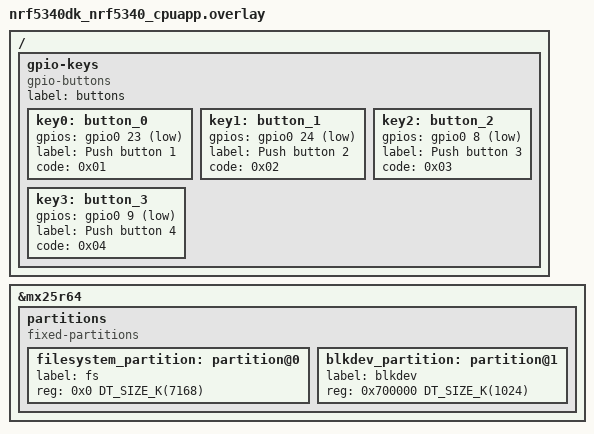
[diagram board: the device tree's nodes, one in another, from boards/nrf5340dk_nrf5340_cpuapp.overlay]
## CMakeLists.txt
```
# Application
cmake_minimum_required(VERSION 3.13.1)

include(../cmake/modules.cmake)
find_package(Zephyr REQUIRED HINTS $ENV{ZEPHYR_BASE})
project(firmware)

#=======================
# User extension
#=======================
include(../cmake/extensions.cmake)
include(../cmake/debugger.cmake)

#=======================
# Global include path
#=======================
zephyr_include_directories(.)

#===========================
# Subdirectories and target
#===========================
add_subdirectory(component)
target_sources(app PRIVATE
  src/main.c
  src/apple_ancs.c
  src/apple_ams.c
  src/bt_disc.c
  src/timer_ii.c
  src/timer_ii_zephyr.c
  src/timer_ii_test.c
)
collect_link_libraries(applibs app)
target_link_libraries(app PUBLIC ${applibs})
```

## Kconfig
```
#Application
menu "Application configuration"
rsource "component/Kconfig"
endmenu

# System
source "Kconfig.zephyr"
```

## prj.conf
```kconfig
CONFIG_BT=y
CONFIG_BT_DEBUG_LOG=y
CONFIG_BT_SMP=y
CONFIG_BT_PERIPHERAL=y
CONFIG_BT_DIS=y
CONFIG_BT_DIS_PNP=n
CONFIG_BT_BAS=y
CONFIG_BT_HRS=y
CONFIG_BT_DEVICE_NAME="ZephyrBLE"
CONFIG_BT_DEVICE_APPEARANCE=833

#Filesystem 
CONFIG_NVS=y

#Settings
CONFIG_SETTINGS=y
CONFIG_SETTINGS_NVS=y

CONFIG_USER_LIBRARIES=y
CONFIG_CORTEXM_DEBUGGER=y

CONFIG_LOG=y
CONFIG_LOG_BACKEND_UART=y

CONFIG_CACHE_MANAGEMENT=y
CONFIG_DCACHE_LINE_SIZE=32
CONFIG_ICACHE_LINE_SIZE=32

CONFIG_HEAP_MEM_POOL_SIZE=65536

# Debug
CONFIG_ASSERT=y

#RootKit
CONFIG_BT_ANCS_CLIENT=y
CONFIG_BT_ANCS_CLIENT_CP_BUFF_SIZE=256
CONFIG_BT_GATT_DM=y
CONFIG_BT_AMS_CLIENT=y
CONFIG_BT_GATTP=y
```

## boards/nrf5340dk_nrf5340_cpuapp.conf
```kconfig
#======================
# ARM options
#======================
CONFIG_NULL_POINTER_EXCEPTION_DETECTION_MPU=y

#======================
# Kernel
#======================
CONFIG_MAIN_STACK_SIZE=2048
CONFIG_SCHED_MULTIQ=y
CONFIG_THREAD_MONITOR=y
CONFIG_THREAD_NAME=y
CONFIG_THREAD_RUNTIME_STATS=y
CONFIG_SYSTEM_WORKQUEUE_STACK_SIZE=2048
CONFIG_KERNEL_MEM_POOL=y
CONFIG_HEAP_MEM_POOL_SIZE=65536

#======================
# Cache
#======================
CONFIG_CACHE_MANAGEMENT=y

#======================
# FPU
#======================
CONFIG_FPU=y
CONFIG_FPU_SHARING=y

#======================
# Subsystem
#======================

# BLE-HOST
CONFIG_BT_SHELL=y
CONFIG_BT=y
CONFIG_BT_HCI=y

CONFIG_BT_BUF_ACL_TX_SIZE=251
CONFIG_BT_BUF_ACL_RX_SIZE=512

CONFIG_BT_DEVICE_NAME_DYNAMIC=y
CONFIG_BT_DEVICE_NAME_MAX=32
CONFIG_BT_DEVICE_NAME="NordicBLE"
CONFIG_BT_COMPANY_ID=0x05F1

CONFIG_BT_DEBUG_LOG=y
CONFIG_BT_PERIPHERAL=y
CONFIG_BT_DIS=y
CONFIG_BT_HCI_ACL_FLOW_CONTROL=y
CONFIG_BT_PHY_UPDATE=y
CONFIG_BT_DATA_LEN_UPDATE=y
CONFIG_BT_SMP=y

CONFIG_BT_L2CAP_TX_BUF_COUNT=6
CONFIG_BT_L2CAP_TX_FRAG_COUNT=4
CONFIG_BT_L2CAP_TX_MTU=256

CONFIG_BT_GATT_SERVICE_CHANGED=y
CONFIG_BT_GATT_CLIENT=y
CONFIG_BT_GATT_READ_MULTIPLE=y

CONFIG_BT_GAP_AUTO_UPDATE_CONN_PARAMS=y
CONFIG_BT_GAP_PERIPHERAL_PREF_PARAMS=y
CONFIG_BT_PERIPHERAL_PREF_MIN_INT=24
CONFIG_BT_PERIPHERAL_PREF_MAX_INT=40
CONFIG_BT_PERIPHERAL_PREF_LATENCY=0
CONFIG_BT_PERIPHERAL_PREF_TIMEOUT=42

CONFIG_BT_HCI_VS=y
CONFIG_BT_HCI_VS_EXT=y
CONFIG_BT_RX_STACK_SIZE=4096
CONFIG_BT_SETTINGS=y
#CONFIG_BT_SHELL=y

# USB
CONFIG_USB_DEVICE_STACK=y
CONFIG_USB_MAX_NUM_TRANSFERS=8
CONFIG_USB_REQUEST_BUFFER_SIZE=512
CONFIG_USB_MASS_STORAGE=y
CONFIG_MASS_STORAGE_DISK_NAME="NAND"
CONFIG_USB_DEVICE_MANUFACTURER="Nordic"
CONFIG_MASS_STORAGE_INQ_VENDOR_ID="Norflash"
CONFIG_MASS_STORAGE_INQ_PRODUCT_ID="USB-Disk        "
CONFIG_USB_DEVICE_VID=0xFFFF
CONFIG_USB_DEVICE_PID=0x1234

#Flash map
CONFIG_FLASH_MAP=y

# Filesystem
CONFIG_FILE_SYSTEM=y
CONFIG_FILE_SYSTEM_SHELL=y

# Little fs
# CONFIG_FILE_SYSTEM_LITTLEFS=y
# CONFIG_FS_LITTLEFS_NUM_FILES=4
# CONFIG_FS_LITTLEFS_NUM_DIRS=4
# CONFIG_FS_LITTLEFS_READ_SIZE=512
# CONFIG_FS_LITTLEFS_PROG_SIZE=512
# CONFIG_FS_LITTLEFS_CACHE_SIZE=4096
# CONFIG_FS_LITTLEFS_LOOKAHEAD_SIZE=128

# Fat
CONFIG_FAT_FILESYSTEM_ELM=y
CONFIG_FS_FATFS_EXFAT=y
CONFIG_FS_FATFS_NUM_FILES=4
CONFIG_FS_FATFS_NUM_DIRS=4
CONFIG_FS_FATFS_LFN=y
CONFIG_FS_FATFS_LFN_MODE_HEAP=y


# Shell
CONFIG_SHELL=y
#CONFIG_UART_SHELL_ON_DEV_NAME="UART_0"

# System monitor
CONFIG_THREAD_ANALYZER=y

# Statistics support
CONFIG_STATS=y
CONFIG_STATS_NAMES=y

#=======================
# Device drivers
#=======================

#Flash driver
CONFIG_FLASH=y
#CONFIG_FLASH_HAS_PAGE_LAYOUT=y
CONFIG_NORDIC_QSPI_NOR=y
CONFIG_NORDIC_QSPI_NOR_FLASH_LAYOUT_PAGE_SIZE=4096

# Disk driver for flash
CONFIG_DISK_DRIVER_FLASH=y
CONFIG_DISK_FLASH_VOLUME_NAME="NAND"
CONFIG_DISK_FLASH_DEV_NAME="MX25R64"
CONFIG_DISK_FLASH_START=0x0
CONFIG_DISK_FLASH_MAX_RW_SIZE=512
CONFIG_DISK_FLASH_ERASE_ALIGNMENT=0x1000
CONFIG_DISK_ERASE_BLOCK_SIZE=0x1000
CONFIG_DISK_FLASH_SECTOR_SIZE=512
CONFIG_DISK_VOLUME_SIZE=0x800000

# BT
CONFIG_BT_RPMSG=y
CONFIG_BT_RPMSG_NRF53=y
CONFIG_BT_DRIVER_QUIRK_NO_AUTO_DLE=y

# IPM
CONFIG_IPM=y
CONFIG_IPM_NRFX=y
CONFIG_IPM_MSG_CH_0_ENABLE=y
CONFIG_IPM_MSG_CH_0_TX=y
CONFIG_IPM_MSG_CH_1_ENABLE=y
CONFIG_IPM_MSG_CH_1_RX=y

# PWM
CONFIG_PWM=y
CONFIG_PWM_NRFX=y
CONFIG_PWM_SHELL=y

# USB
CONFIG_USB_DEVICE_DRIVER=y
CONFIG_USB_NRFX=y

# Kscan
CONFIG_KSCAN=y

#=======================
# C Library
#=======================
CONFIG_NEWLIB_LIBC=y


#=======================
# Compile options
#=======================
# CONFIG_SPEED_OPTIMIZATIONS=y
CONFIG_DEBUG_OPTIMIZATIONS=y


#=========================
# RootKit
#=========================

# Drivers
#CONFIG_GPIO_KEYS=y

# Lib
CONFIG_USER_SYSTEM_INIT=y
CONFIG_USER_FS_MOUNT=y

# Subsystem
CONFIG_USER_SUBSYSTEM=y
CONFIG_BDBUF=y
```

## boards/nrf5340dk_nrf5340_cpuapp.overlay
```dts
/ {
	gpio-keys {
		compatible = "gpio-buttons";
		label = "buttons";
		key0: button_0 {
			gpios = <&gpio0 23 (GPIO_PULL_UP | GPIO_ACTIVE_LOW)>;
			label = "Push button 1";
			code = <0x01>;
		};
		key1: button_1 {
			gpios = <&gpio0 24 (GPIO_PULL_UP | GPIO_ACTIVE_LOW)>;
			label = "Push button 2";
			code = <0x02>;
		};
		key2: button_2 {
			gpios = <&gpio0 8 (GPIO_PULL_UP | GPIO_ACTIVE_LOW)>;
			label = "Push button 3";
			code = <0x03>;
		};
		key3: button_3 {
			gpios = <&gpio0 9 (GPIO_PULL_UP | GPIO_ACTIVE_LOW)>;
			label = "Push button 4";
			code = <0x04>;
		};
	};
};

&mx25r64 {
	partitions {
		compatible = "fixed-partitions";
		#address-cells = <1>;
		#size-cells = <1>;

		filesystem_partition: partition@0 {
			label = "fs";
			reg = <0x0 DT_SIZE_K(7168)>;
		};
		blkdev_partition: partition@1 {
			label = "blkdev";
			reg = <0x700000 DT_SIZE_K(1024)>;
		};
	};
};
```

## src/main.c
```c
/*
 * Copyright(C) 2021
 * Author: wtcat
 */

#include <errno.h>
#include <string.h>
#include <sys/byteorder.h>
#include <sys/printk.h>

#include <device.h>
#include <drivers/kscan.h>
#include <zephyr.h>

#include <bluetooth/bluetooth.h>
#include <bluetooth/gatt.h>
#include <bluetooth/services/bas.h>
#include <bluetooth/services/hrs.h>

#include <logging/log.h>
#include <usb/usb_device.h>

#include "blkdev/bdbuf.h"
#include "component/bt/bthost_init.h"

#include "debugger/core_debug.h"

LOG_MODULE_REGISTER(main);

//#define USE_BREAKPOINT_TEST

extern void bt_apple_ancs_ready(int err);

#if defined(USE_BREAKPOINT_TEST)
volatile int __test_var = 1;
#endif

static void bas_notify(void) {
  uint8_t battery_level = bt_bas_get_battery_level();
  battery_level--;
  if (!battery_level)
    battery_level = 100U;
  bt_bas_set_battery_level(battery_level);
}

static void hrs_notify(void) {
  static uint8_t heartrate = 90U;
  /* Heartrate measurements simulation */
  heartrate++;
  if (heartrate == 160U)
    heartrate = 90U;
  bt_hrs_notify(heartrate);
}

static void keyboard_notify(const struct device *dev, uint32_t row,
                            uint32_t column, bool pressed) {
  printk("Key(%u): %s\n", row, pressed ? "Pressed" : "Released");
}

static void blkdev_test(void) {
  struct k_blkdev *bdev;
  char buffer[32] = {"Hello, world!"};
  bdev = k_blkdev_get("blkdev");
  if (!bdev)
    return;
  k_blkdev_write(bdev, buffer, strlen(buffer), 0);
  memset(buffer, 0, sizeof(buffer));
  k_blkdev_read(bdev, buffer, 13, 0);
  printk("%s\n", buffer);
}

int main(void) {
  int err;

#if defined(USE_BREAKPOINT_TEST)
  core_watchpoint_install(3, &__test_var, MEM_WRITE | MEM_SIZE_1);
#endif
  malloc(16);
  // blkdev_test();
  //err = bt_enable(bt_host_default_ready_cb);
   err = bt_enable(bt_apple_ancs_ready);
  if (err)
     LOG_ERR("Bluetooth initialize failed(%d)\n", err);
    
  /* Implement notification. At the moment there is no suitable way
   * of starting delayed work so we do it here
   */
  const struct device *key = device_get_binding("buttons");
  if (key) {
    kscan_config(key, keyboard_notify);
    kscan_enable_callback(key);
  }

#if defined(USE_BREAKPOINT_TEST)
  if (__test_var == 1)
    __test_var = 2;
  core_watchpoint_uninstall(3);
#endif
  err = usb_enable(NULL);
  if (err != 0) {
    LOG_ERR("Failed to enable USB");
  }
  for (;;) {
    k_sleep(K_SECONDS(1));

    // /* Heartrate measurements simulation */
    // hrs_notify();

    // /* Battery level simulation */
    // bas_notify();
  }
  return 0;
}
```

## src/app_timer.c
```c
//#include "ydy_boards_config.h"
//#if (DEBUG_PART_ENABLE ==1)
//#define DEBUG_INFO_ENABLE			1
//#define DEBUG_ERROR_ENABLE		1
//#define DEBUG_INFO_ENABLE		1
//#define DEBUG_FUN_ENABLE			0
//#endif


//#define DEBUG_STRING "[APP TIMER]"

#define TIMER_MERGE_ENABLE 

#include <stdlib.h>
#include <string.h>
#include <assert.h>

#include <zephyr.h>

#include "app_timer.h"



#define ERROR_CODE_SUCCESS 0
#define ERROR_CODE_INVALID_PARAM 1
#define ERROR_CODE_INVALID_STATE 2

#define DEBUG_INFO(...)
#define APP_ERROR_CHECK_BOOL(...)

//hrtimer 的接口单位为us
#define HRTIMER_MSEC(MS) (MS * 1000)

static void app_timer_callback(struct k_timer *ttimer);

typedef struct
{
    app_timer_timeout_handler_t timeout_handler;
    void *                      p_context;
} app_timer_event_t;

#ifdef TIMER_MERGE_ENABLE
#include "timer_patch.h"
#endif

static void timeout_handler_scheduled_exec(void * p_event_data, uint16_t event_size)
{
    APP_ERROR_CHECK_BOOL(event_size == sizeof(app_timer_event_t));
    app_timer_event_t const * p_timer_event = (app_timer_event_t *)p_event_data;
	
    p_timer_event->timeout_handler(p_timer_event->p_context);
}

static void app_timer_callback(struct k_timer *ttimer)
{
    app_timer_t *ptimer = (app_timer_t*)(ttimer);

    if(ptimer->active == false)
    {
        return ;
    }
    
    if(ptimer->func == NULL)
    {
        return ;
    }

    if(ptimer->active)
    {
    	if (!ptimer->isr_context) {
			/*
			 * Task Context
			 */
	        ptimer->active = (ptimer->single_shot) ? false : true;
	        app_timer_event_t timer_event;
	        timer_event.p_context = ptimer->argument;
	        timer_event.timeout_handler = ptimer->func;

        DEBUG_INFO("app_timer_callback = %X",ptimer->func);

        uint32_t err_code;

	        //err_code = app_sched_event_put(&timer_event, sizeof(timer_event), timeout_handler_scheduled_exec);
	        //APP_ERROR_CHECK(err_code);
    	} else {
			/*
			 * Interrupt Context
			 */
			ptimer->func(ptimer->argument);
    	}

        if (!ptimer->single_shot)
        {
      #ifdef TIMER_MERGE_ENABLE
			abstract_timer_start(ptimer, ptimer->timeout);
	  #else
            k_timer_start(&ptimer->timer, K_MSEC(ptimer->timeout), K_NO_WAIT);
			//hrtimer_start(&ptimer->timer, HRTIMER_MSEC(ptimer->timeout), 0);
	  #endif
        }
    }
}

uint32_t app_timer_init()
{
    return ERROR_CODE_SUCCESS;
}

uint32_t app_timer_create(app_timer_id_t const *p_timer_id,
	                          app_timer_mode_t mode,
    	                      app_timer_timeout_handler_t timeout_handler)
{
    app_timer_t *ptimer = (app_timer_t*)(*p_timer_id);
    uint32_t    err_code = ERROR_CODE_SUCCESS;

    if((timeout_handler == NULL) || (p_timer_id == NULL))
    {
        return ERROR_CODE_INVALID_PARAM;
    }
    if(ptimer->active)
    {
        return ERROR_CODE_INVALID_STATE;
    }

	memset(ptimer, 0, sizeof(app_timer_t));

	ptimer->single_shot = (APP_TIMER_MODE(mode) == APP_TIMER_MODE_SINGLE_SHOT);
	ptimer->isr_context = !!(mode & APP_TIMER_ISR_CONTEXT);
	ptimer->func = timeout_handler;
 
    k_timer_init(&ptimer->timer, app_timer_callback, NULL);
	// hrtimer_init(&ptimer->timer,
	// 			 app_timer_callback,
	// 			 NULL);

    return err_code;
}


uint32_t app_timer_start(app_timer_id_t timer_id,
								uint32_t timeout_ms,
								void * p_context)
{
    app_timer_t * ptimer = (app_timer_t*)(timer_id);

    ptimer->timeout = timeout_ms;
    ptimer->argument = p_context;
    ptimer->active = true;
#ifdef TIMER_MERGE_ENABLE
	abstract_timer_reset(ptimer, timeout_ms);
	abstract_timer_start(ptimer, timeout_ms);
	abstract_timer_post(ptimer);
#else
    k_timer_start(&ptimer->timer, K_MSEC(timeout_ms), K_NO_WAIT);
	//hrtimer_start(&ptimer->timer, HRTIMER_MSEC(timeout_ms), 0);
#endif
    return ERROR_CODE_SUCCESS;
}

uint32_t app_timer_is_valide(app_timer_id_t timer_id)
{
	if(timer_id == NULL)
    {
        return 0;
    };
	
	return 1;
}

uint32_t app_timer_stop(app_timer_id_t timer_id)
{
    app_timer_t * ptimer = (app_timer_t*)(timer_id);
#ifdef TIMER_MERGE_ENABLE
	abstract_timer_stop(ptimer);
#else
    k_timer_stop(&ptimer->timer);
	//hrtimer_stop(&ptimer->timer);
#endif

    return ERROR_CODE_SUCCESS;
}
```

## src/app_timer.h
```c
#ifndef APP_TIMER_H
#define APP_TIMER_H


//*****************************************************************************
//	app_timer.h
//		应用定时器
//
// Copyright (c) 2018, Idoo
// All rights reserved.
//
// 修订历史：
//		2018.6.22, Yannick: 创建，根据 nordic 移植 FreeRtos 代码
//		2018.7.21, yannick: 修订，优化为 eventgroup 方式
//      2021.4.10, jiangbin: 修订，适配成zephyr实现，并适当优化
//*****************************************************************************

#include <stdint.h>
#include <stdbool.h>
#include <stdio.h>
#include <zephyr.h>
//#include <drivers/hrtimer.h>

#include "timer_ii.h"

/* Convert milliseconds to timer ticks. */
#define APP_TIMER_TICKS(MS) MS

//Application time-out handler type.
typedef void(*app_timer_timeout_handler_t) (void * p_context);

/**@brief This structure keeps information about osTimer.*/
typedef struct
{
	union {
    	struct k_timer          timer;
		struct timer_struct     timer_ii;
	};
    void *						argument;

    //time out(ms)
    uint32_t                    timeout;
    app_timer_timeout_handler_t	func;
    /*保证定时器是在运行状态下，绕过 FreeRTOS 一些问题 */
	uint8_t                     active:1;
	uint8_t                     single_shot:1;
	uint8_t					    isr_context:1;
	uint8_t                     is_timer_ii:1;
}app_timer_t;

/* Timer ID type.
 * Never declare a variable of this type, but use the macro @ref APP_TIMER_DEF instead.*/
typedef app_timer_t * app_timer_id_t;

/* Create a timer identifier and statically allocate memory for the timer.
 *
 * @param timer_id Name of the timer identifier variable that will be used to control the timer.
 */
#define APP_TIMER_DEF(timer_id)                                  \
    static app_timer_t timer_id##_data = {0};                  \
    static const app_timer_id_t timer_id = &timer_id##_data

/**@brief Timer modes. */
	
#define APP_TIMER_ISR_CONTEXT 0x80
#define APP_TIMER_MODE_MASK   0x0F
#define APP_TIMER_MODE(m) ((m) & APP_TIMER_MODE_MASK)
typedef enum 
{
    APP_TIMER_MODE_SINGLE_SHOT, 				/**< The timer will expire only once. */
    APP_TIMER_MODE_REPEATED, 					/**< The timer will restart each time it expires. */	    
    APP_TIMER_MODE_SINGLE_SHOT_ISR = APP_TIMER_MODE_SINGLE_SHOT | APP_TIMER_ISR_CONTEXT,
    APP_TIMER_MODE_REPEATED_ISR    = APP_TIMER_MODE_REPEATED | APP_TIMER_ISR_CONTEXT
} app_timer_mode_t;

/****************************************************************************/
/*	int app_timer_init(void)												*/
/*	模块初始化																	*/
/*	返回值是ERROR_CODE_SUCCESS或其它出错代码													*/
/****************************************************************************/
uint32_t app_timer_init(void);

/**@brief Function for creating a timer instance.
 *
 * @param[in]  p_timer_id        Pointer to timer identifier.
 * @param[in]  mode              Timer mode.
 * @param[in]  timeout_handler   Function to be executed when the timer expires.
 *
 * @retval     ERROR_CODE_SUCCESS               If the timer was successfully created.
 * @retval     ERROR_CODE_INVALID_PARAM   If a parameter was invalid.
 * @retval     ERROR_CODE_INVALID_STATE   If the application timer module has not been initialized or
 *                                       the timer is running.
 *
 * @note This function does the timer allocation in the caller's context. It is also not protected
 *       by a critical region. Therefore care must be taken not to call it from several interrupt
 *       levels simultaneously.
 * @note The function can be called again on the timer instance and will re-initialize the instance if
 *       the timer is not running.
 * @attention The FreeRTOS and RTX app_timer implementation does not allow app_timer_create to
 *       be called on the previously initialized instance.
 */
uint32_t app_timer_create(app_timer_id_t const *p_timer_id,
                       				app_timer_mode_t mode,
                          			app_timer_timeout_handler_t timeout_handler);

/**@brief Function for starting a timer.
 *
 * @param[in]		timer_id	  Timer identifier.
 * @param[in]		timeout_ms    Number of ms to time-out event
 * @param[in]		p_context	  General purpose pointer. Will be passed to the time-out handler when
 *								  the timer expires.
 *
 * @retval	   ERROR_CODE_SUCCESS				 If the timer was successfully started.
 * @retval	   ERROR_CODE_INVALID_PARAM	 If a parameter was invalid.
 * @retval	   ERROR_CODE_INVALID_STATE	 If the application timer module has not been initialized or the timer
 *										 has not been created.
 * @retval	   ERROR_CODE_NO_MEM 		 If the timer operations queue was full.
 *
 * @note For multiple active timers, time-outs occurring in close proximity to each other (in the
 *		 range of 1 to 3 ticks) will have a positive jitter of maximum 3 ticks.
 * @note When calling this method on a timer that is already running, the second start operation
 *		 is ignored.
 */
uint32_t app_timer_start(app_timer_id_t timer_id, uint32_t timeou_ms, void * p_context);

/**@brief Function for stopping the specified timer.
 *
 * @param[in]  timer_id 				 Timer identifier.
 *
 * @retval	   ERROR_CODE_SUCCESS				 If the timer was successfully stopped.
 * @retval	   ERROR_CODE_INVALID_PARAM	 If a parameter was invalid.
 * @retval	   ERROR_CODE_INVALID_STATE	 If the application timer module has not been initialized or the timer
 *										 has not been created.
 * @retval	   ERROR_CODE_NO_MEM 		 If the timer operations queue was full.
 */
uint32_t app_timer_stop(app_timer_id_t timer_id);

/**@brief Function for stopping all running timers.
 *
 * @retval	   ERROR_CODE_SUCCESS				 If all timers were successfully stopped.
 * @retval	   ERROR_CODE_INVALID_STATE	 If the application timer module has not been initialized.
 * @retval	   ERROR_CODE_NO_MEM 		 If the timer operations queue was full.
 */
uint32_t app_timer_stop_all(void);

/**@brief Function for get timer is valide.
 *
 * @param[in]  timer_id 				 Timer identifier.
 *
 * @retval	   1	valid
 * @retval	   0	invalid
 */
uint32_t app_timer_is_valide(app_timer_id_t timer_id);

#endif
```

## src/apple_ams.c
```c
#include <zephyr.h>
#include <bluetooth/conn.h>
#include <bluetooth/gatt.h>
#include <bluetooth/hci.h>
#include <bluetooth/uuid.h>

#include <bluetooth/gatt_dm.h>
#include <bluetooth/services/ams_client.h>

#include <logging/log.h>

#include "bt_disc.h"

LOG_MODULE_REGISTER(bt_ams);

static struct bt_ams_client ams_instance;
static const enum bt_ams_track_attribute_id entity_update_track[] = {
	BT_AMS_TRACK_ATTRIBUTE_ID_ARTIST,
	BT_AMS_TRACK_ATTRIBUTE_ID_ALBUM,
	BT_AMS_TRACK_ATTRIBUTE_ID_TITLE,
	BT_AMS_TRACK_ATTRIBUTE_ID_DURATION
};

static char msg_buff[400 + 1];
static void ams_read_entity_cb(struct bt_ams_client *ams_c, uint8_t err, 
	const uint8_t *data, size_t len) {
	if (!err) {
		memcpy(msg_buff, data, len);
		msg_buff[len] = '\0';
		printk("AMS EA: %s\n", msg_buff);
	} else {
		printk("AMS EA read error 0x%02X\n", err);
	}
}

static void ams_remote_command_notify(struct bt_ams_client *ams_c,
	const uint8_t *data, size_t len) {
	size_t i;
	char str_hex[4];
	if (len > 0) {
		/* Print the accepted Remote Command values. */
		sprintf(msg_buff, "%02X", *data);
		for (i = 1; i < len; i++) {
			sprintf(str_hex, ",%02X", *(data + i));
			strcat(msg_buff, str_hex);
		}
		printk("AMS RC: %s\n", msg_buff);
	}
}

static void ams_write_entity_update_cb(struct bt_ams_client *ams_c, uint8_t err) {
	if (!err) {
		err = bt_ams_read_entity_attribute(ams_c, ams_read_entity_cb);
	} else {
		printk("AMS EA write error 0x%02X\n", err);
	}
}

static void ams_entity_updated_notify(struct bt_ams_client *ams_c,
	const struct bt_ams_entity_update_notif *notif, int err) {
	uint8_t attr_val;
	char str_hex[9];
	if (err) {
		LOG_WRN("AMS entity update invalid\n");
		return;
	}
	switch(notif->ent_attr.entity) {
	case BT_AMS_ENTITY_ID_PLAYER:
		attr_val = notif->ent_attr.attribute.player;
		break;
	case BT_AMS_ENTITY_ID_QUEUE:
		attr_val = notif->ent_attr.attribute.queue;
		break;
	case BT_AMS_ENTITY_ID_TRACK:
		attr_val = notif->ent_attr.attribute.track;
		break;
	default:
		err = -EINVAL;
	}

	sprintf(str_hex, "%02X,%02X,%02X", notif->ent_attr.entity, 
		attr_val, notif->flags);
	memcpy(msg_buff, notif->data, notif->len);
	msg_buff[notif->len] = '\0';
	printk("AMS EU: %s %s\n", str_hex, msg_buff);
	if(attr_val == BT_AMS_ENTITY_ID_PLAYER)
	{
		//ios_msg_protocol_handle(IOS_AMS_MUSIC_PLAYER,&msg_buff,strlen(msg_buff));
	}
	else if(attr_val == BT_AMS_ENTITY_ID_TRACK)
	{
		//ios_msg_protocol_handle(IOS_AMS_MUSIC_NAME,&msg_buff,strlen(msg_buff));
	}
	/* Read truncated song title. */
	if (notif->ent_attr.entity == BT_AMS_ENTITY_ID_TRACK &&
		notif->ent_attr.attribute.track == BT_AMS_TRACK_ATTRIBUTE_ID_TITLE &&
		(notif->flags & BIT(BT_AMS_ENTITY_UPDATE_FLAG_TRUNCATED))) {
		err = bt_ams_write_entity_attribute(ams_c, &notif->ent_attr, 
			ams_write_entity_update_cb);
		if (err) 
			LOG_ERR("Cannot write to Entity Attribute (err %d)", err);
	}
}

static void ams_write_entity_cb(struct bt_ams_client *ams, 
	uint8_t err) {
	if (err) {
		LOG_ERR("AMS EU write error 0x%02X\n", err);
	}
}

static void ams_notifications_enable(struct bt_ams_client *ams) {
	struct bt_ams_entity_attribute_list list;
	int err = bt_ams_subscribe_remote_command(ams, ams_remote_command_notify);
	if (err) {
		LOG_ERR("Cannot subscribe to Remote Command notification (err %d)\n", err);
		return;
	}
	err = bt_ams_subscribe_entity_update(ams, ams_entity_updated_notify);
	if (err) {
		LOG_ERR("Cannot subscribe to Entity Update notification (err %d)\n", err);
		return;
	}
	list.entity = BT_AMS_ENTITY_ID_TRACK;
	list.attribute.track = entity_update_track;
	list.attribute_count = ARRAY_SIZE(entity_update_track);
	err = bt_ams_write_entity_update(ams, &list, ams_write_entity_cb);
	if (err) 
		LOG_ERR("Cannot write to Entity Update (err %d)\n", err);
}

static void ams_discover_completed(struct bt_gatt_dm *dm, void *ctx) {
	struct bt_ams_client *ams = (struct bt_ams_client *)ctx;
	struct bt_conn *conn = bt_gatt_dm_conn_get(dm);
	LOG_INF("The AMS discovery procedure succeeded\n");
	bt_gatt_dm_data_print(dm);
	int err = bt_ams_handles_assign(dm, ams);
	if (err) 
		LOG_ERR("Could not init AMS client object, error: %d\n", err);
	else
		ams_notifications_enable(ams);
	err = bt_gatt_dm_data_release(dm);
	if (err) {
		LOG_ERR("Could not release the discovery data, error "
		       "code: %d\n", err);
	}
	bt_discovery_start(conn);
}

static void ams_discover_not_found(struct bt_conn *conn, void *ctx) {
	LOG_WRN("The AMS could not be found during the discovery\n");
	bt_discovery_finish(conn, false);
}

static void ams_discover_error_found(struct bt_conn *conn, int err, 
    void *ctx) {
	LOG_WRN("The AMS discovery procedure failed, err %d\n", err);
	bt_discovery_finish(conn, false);
}

static const struct bt_gatt_dm_cb discover_ams_cb = {
	.completed = ams_discover_completed,
	.service_not_found = ams_discover_not_found,
	.error_found = ams_discover_error_found,
};

static int ams_discover(struct bt_conn *conn) {
	return bt_gatt_dm_start(conn, BT_UUID_AMS, &discover_ams_cb, 
		&ams_instance);
}

static void ams_remote_command_write_cb(struct bt_ams_client *ams, 
	uint8_t err) {
	if (err) {
		LOG_ERR("AMS RC write error 0x%02x\n", (int)err);
	}
}

int ams_remote_command_send(enum bt_ams_remote_command_id cmd,
	bt_ams_write_cb cb) {
	return bt_ams_write_remote_command(&ams_instance, cmd, 
		cb? cb: ams_remote_command_write_cb);			  
}

int ams_init(void) {
	static struct bt_disc_node dn = {
		.name     = "AMS",
		.discover = ams_discover
	};
	int err = bt_gattp_discovery_register(&dn);
	if (!err)
		return bt_ams_client_init(&ams_instance);
	return err;
}
```

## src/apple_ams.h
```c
#ifndef APPLE_AMS_H_
#define APPLE_AMS_H_

#include <bluetooth/services/ams_client.h>

#ifdef __cplusplus
extern "C"{
#endif

int ams_init(void);
int ams_remote_command_send(enum bt_ams_remote_command_id cmd,
	bt_ams_write_cb done);

#ifdef __cplusplus
}
#endif
#endif /* APPLE_AMS_H_ */
```

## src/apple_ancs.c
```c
/*
 * Copyright (c) 2021 Nordic Semiconductor ASA
 *
 * SPDX-License-Identifier: LicenseRef-Nordic-5-Clause
 */

#include <zephyr.h>
#include <sys/printk.h>
#include <sys/byteorder.h>

#include <bluetooth/bluetooth.h>
#include <bluetooth/conn.h>
#include <bluetooth/uuid.h>
#include <bluetooth/gatt.h>
#include <bluetooth/gatt_dm.h>
#include <bluetooth/services/ancs_client.h>
#include <bluetooth/services/gattp.h>

#include <logging/log.h>
#include <settings/settings.h>

#include "apple_ancs.h"
#include "bt_disc.h"

LOG_MODULE_REGISTER(app_ancs);

#define DEBUG_ANCS


#define DEVICE_NAME     CONFIG_BT_DEVICE_NAME
#define DEVICE_NAME_LEN sizeof(DEVICE_NAME)

/* Allocated size for attribute data. */
#define ATTR_DATA_SIZE BT_ANCS_ATTR_DATA_MAX

enum {
	DISCOVERY_ANCS_ONGOING,
	DISCOVERY_ANCS_SUCCEEDED,
	SERVICE_CHANGED_INDICATED
};

static const struct bt_data ad[] = {
	BT_DATA_BYTES(BT_DATA_FLAGS, (BT_LE_AD_GENERAL | BT_LE_AD_NO_BREDR)),
	BT_DATA_BYTES(BT_DATA_SOLICIT128, BT_UUID_ANCS_VAL)
};


static struct bt_ancs_client ancs_c;

/* Local copy to keep track of the newest arriving notifications. */
static struct bt_ancs_evt_notif notification_latest;

/* Buffers to store attribute data. */
static uint8_t attr_appid[ATTR_DATA_SIZE];
static uint8_t attr_title[ATTR_DATA_SIZE];
static uint8_t attr_subtitle[ATTR_DATA_SIZE];
static uint8_t attr_message[ATTR_DATA_SIZE];
static uint8_t attr_message_size[ATTR_DATA_SIZE];
static uint8_t attr_date[ATTR_DATA_SIZE];
static uint8_t attr_posaction[ATTR_DATA_SIZE];
static uint8_t attr_negaction[ATTR_DATA_SIZE];
static uint8_t attr_disp_name[ATTR_DATA_SIZE];

static ancs_notification_handler_t ancs_notification_cb;
static ancs_data_handler_t ancs_data_cb;


#if defined(DEBUG_ANCS)
static const char *lit_catid[BT_ANCS_CATEGORY_ID_COUNT] = {
	"Other",
	"Incoming Call",
	"Missed Call",
	"Voice Mail",
	"Social",
	"Schedule",
	"Email",
	"News",
	"Health And Fitness",
	"Business And Finance",
	"Location",
	"Entertainment"
};

const char *lit_eventid[BT_ANCS_EVT_ID_COUNT] = { 
	"Added", "Modified", "Removed" 
};
							 
static const char *lit_attrid[BT_ANCS_NOTIF_ATTR_COUNT] = {
	"App Identifier",
	"Title",
	"Subtitle",
	"Message",
	"Message Size",
	"Date",
	"Positive Action Label",
	"Negative Action Label"
};
#endif

static const char *lit_appid[BT_ANCS_APP_ATTR_COUNT] = { "Display Name" };


#if defined(DEBUG_ANCS)
static void notif_print(const struct bt_ancs_evt_notif *notif) {
	LOG_INF("\nNotification\n");
	LOG_INF("Event:       %s\n", lit_eventid[notif->evt_id]);
	LOG_INF("Category ID: %s\n", lit_catid[notif->category_id]);
	LOG_INF("Category Cnt:%u\n", (unsigned int)notif->category_count);
	LOG_INF("UID:         %u\n", (unsigned int)notif->notif_uid);
	LOG_INF("Flags:\n");
	if (notif->evt_flags.silent) 
		LOG_INF(" Silent\n");
	if (notif->evt_flags.important) 
		LOG_INF(" Important\n");
	if (notif->evt_flags.pre_existing) 
		LOG_INF(" Pre-existing\n");
	if (notif->evt_flags.positive_action) 
		LOG_INF(" Positive Action\n");
	if (notif->evt_flags.negative_action) 
		LOG_INF(" Negative Action\n");
}

static void notif_attr_print(const struct bt_ancs_attr *attr) {
	if (attr->attr_len != 0) {
		LOG_INF("%s: %s\n", lit_attrid[attr->attr_id],
		       log_strdup((char *)attr->attr_data));
	} else if (attr->attr_len == 0) {
		LOG_INF("%s: (N/A)\n", lit_attrid[attr->attr_id]);
	}
}

static void app_attr_print(const struct bt_ancs_attr *attr) {
	if (attr->attr_len != 0) {
		LOG_INF("%s: %s\n", lit_appid[attr->attr_id],
		       log_strdup((char *)attr->attr_data));
	} else if (attr->attr_len == 0) {
		LOG_INF("%s: (N/A)\n", lit_appid[attr->attr_id]);
	}
}

#else /* !DEBUG_ANCS */
#define notif_print(info)      (void)info
#define notif_attr_print(attr) (void)attr
#define app_attr_print(attr)   (void)attr
#endif /* DEBUG_ANCS */

static void ancs_error_code_print(uint8_t err) {
	switch (err) {
	case BT_ATT_ERR_ANCS_NP_UNKNOWN_COMMAND:
		LOG_ERR("Error: Command ID was not recognized by "
			"the Notification Provider.\n");
		break;
	case BT_ATT_ERR_ANCS_NP_INVALID_COMMAND:
		LOG_ERR("Error: Command failed to be parsed on the "
			"Notification Provider.\n");
		break;
	case BT_ATT_ERR_ANCS_NP_INVALID_PARAMETER:
		LOG_ERR("Error: Parameter does not refer to an existing "
			"object on the Notification Provider.\n");
		break;
	case BT_ATT_ERR_ANCS_NP_ACTION_FAILED:
		LOG_ERR("Error: Perform Notification Action Failed on "
			"the Notification Provider.\n");
		break;
	default:
		break;
	}
}

static void bt_ancs_write_done(struct bt_ancs_client *ancs,
	uint8_t err) {
	if (err != 0)
    	ancs_error_code_print(err);
}

static void bt_ancs_notification_source_handler(struct bt_ancs_client *ancs,
		int err, const struct bt_ancs_evt_notif *notif) {
	if (err != 0) {
		LOG_ERR("ANCS notification error(%d)\n", err);
		return;
	}
	notif_print(notif);
	notification_latest = *notif;
	if (ancs_notification_cb)
		ancs_notification_cb(ancs, notif);
	switch (notif->evt_id) {
	case BT_ANCS_EVENT_ID_NOTIFICATION_ADDED:
		if (!notif->evt_flags.pre_existing)
			bt_ancs_request_attrs(ancs, notif, bt_ancs_write_done);
		break;
	case BT_ANCS_EVENT_ID_NOTIFICATION_MODIFIED:
	case BT_ANCS_EVENT_ID_NOTIFICATION_REMOVED:
	default:
		break;
	}
}

static void bt_ancs_data_source_handler(struct bt_ancs_client *ancs,
	const struct bt_ancs_attr_response *rsp) {
	if (ancs_data_cb)
		ancs_data_cb(ancs, rsp);
	switch (rsp->command_id) {
	case BT_ANCS_COMMAND_ID_GET_NOTIF_ATTRIBUTES:
		notif_attr_print(&rsp->attr);
		break;
	case BT_ANCS_COMMAND_ID_GET_APP_ATTRIBUTES:
		app_attr_print(&rsp->attr);
		break;
	case BT_ANCS_COMMAND_ID_PERFORM_NOTIF_ACTION:
	default:
		break;
	}
}

static void enable_ancs_notifications(struct bt_ancs_client *ancs) {
	int err = bt_ancs_subscribe_notification_source(ancs,
			bt_ancs_notification_source_handler);
	if (err) {
		LOG_ERR("Failed to enable Notification "
			"Source notification (err %d)\n", err);
	}
	err = bt_ancs_subscribe_data_source(ancs,
			bt_ancs_data_source_handler);
	if (err) {
		LOG_ERR("Failed to enable Data Source notification (err %d)\n", err); 
	}
}

static void discover_ancs_completed_cb(struct bt_gatt_dm *dm, 
	void *ctx) {
	struct bt_ancs_client *ancs = (struct bt_ancs_client *)ctx;
	struct bt_conn *conn = bt_gatt_dm_conn_get(dm);
	LOG_INF("ANCS discovery completed\n");
	bt_gatt_dm_data_print(dm);
	int err = bt_ancs_handles_assign(dm, ancs);
	if (err) {
		LOG_ERR("Could not init ANCS client object, error: %d\n", err);
	} else {
		enable_ancs_notifications(ancs);
	}
	err = bt_gatt_dm_data_release(dm);
	if (err) {
		LOG_ERR("Could not release the discovery data, error "
		       "code: %d\n", err);
	}
	bt_discovery_start(conn);
}

static void discover_ancs_not_found_cb(struct bt_conn *conn, 
	void *ctx) {
	LOG_WRN("ANCS could not be found during the discovery\n");
	bt_discovery_finish(conn, false);
}

static void discover_ancs_error_found_cb(struct bt_conn *conn, 
	int err, void *ctx) {
	LOG_WRN("The discovery procedure for ANCS failed, err %d\n", err);
	bt_discovery_finish(conn, false);
}

static const struct bt_gatt_dm_cb discover_ancs_cb = {
	.completed = discover_ancs_completed_cb,
	.service_not_found = discover_ancs_not_found_cb,
	.error_found = discover_ancs_error_found_cb,
};

static void connected(struct bt_conn *conn, uint8_t err) {
	int ret;
	char addr[BT_ADDR_LE_STR_LEN];
	if (err) {
		LOG_ERR("Connection failed (err 0x%02x)\n", err);
		return;
	}
	bt_addr_le_to_str(bt_conn_get_dst(conn), addr, sizeof(addr));
	if (bt_conn_get_security(conn) < BT_SECURITY_L2) {
		ret = bt_conn_set_security(conn, BT_SECURITY_L2);
		if (ret) 
			LOG_ERR("Failed to set security (err %d)\n", ret); 
	}
}

static void disconnected(struct bt_conn *conn, uint8_t reason) {
	char addr[BT_ADDR_LE_STR_LEN];
	bt_addr_le_to_str(bt_conn_get_dst(conn), addr, sizeof(addr));
	LOG_WRN("Disconnected from %s (reason 0x%02x)\n", log_strdup(addr), reason);
}

static int ancs_discover(struct bt_conn *conn) {
	return bt_gatt_dm_start(conn, BT_UUID_ANCS,
		 &discover_ancs_cb, &ancs_c);
}

static void security_changed(struct bt_conn *conn, bt_security_t level,
	enum bt_security_err err) {
	char addr[BT_ADDR_LE_STR_LEN];
	bt_addr_le_to_str(bt_conn_get_dst(conn), addr, sizeof(addr));
	if (!err) {
		LOG_INF("Security changed: %s level %u\n", log_strdup(addr), level);
		if (bt_conn_get_security(conn) >= BT_SECURITY_L2)
			bt_gattp_discovery_start(conn);
	} else {
		LOG_ERR("Security failed: %s level %u err %d\n", 
			log_strdup(addr), level, err);  
	}
}

static void auth_cancel(struct bt_conn *conn) {
	char addr[BT_ADDR_LE_STR_LEN];
	bt_addr_le_to_str(bt_conn_get_dst(conn), addr, sizeof(addr));
	LOG_INF("Pairing cancelled: %s\n", log_strdup(addr));
	bt_conn_disconnect(conn, BT_HCI_ERR_REMOTE_USER_TERM_CONN);
}

static void pairing_complete(struct bt_conn *conn, bool bonded) {
	char addr[BT_ADDR_LE_STR_LEN];
	bt_addr_le_to_str(bt_conn_get_dst(conn), addr, sizeof(addr));
	LOG_INF("Pairing completed: %s, bonded: %d\n", log_strdup(addr), bonded);
}

static void pairing_failed(struct bt_conn *conn, 
	enum bt_security_err reason) {
	char addr[BT_ADDR_LE_STR_LEN];
	bt_addr_le_to_str(bt_conn_get_dst(conn), addr, sizeof(addr));
	LOG_ERR("Pairing failed conn: %s, reason %d\n", log_strdup(addr), reason);
	bt_conn_disconnect(conn, BT_HCI_ERR_REMOTE_USER_TERM_CONN);
}

static int bt_ancs_service_init(struct bt_ancs_client *ancs) {
	static struct bt_disc_node disc_nodes = {
		.name     = "ANCS",
		.discover = ancs_discover
	};
	int err = bt_ancs_client_init(ancs);
	if (err) 
		goto _out;
	err = bt_ancs_register_attr(ancs,
		BT_ANCS_NOTIF_ATTR_ID_APP_IDENTIFIER,
		attr_appid, ATTR_DATA_SIZE);
	if (err) 
		goto _out;
	err = bt_ancs_register_app_attr(ancs,
		BT_ANCS_APP_ATTR_ID_DISPLAY_NAME,
		attr_disp_name, sizeof(attr_disp_name));
	if (err) 
		goto _out;
	err = bt_ancs_register_attr(ancs,
		BT_ANCS_NOTIF_ATTR_ID_TITLE,
		attr_title, ATTR_DATA_SIZE);
	if (err) 
		goto _out;
	err = bt_ancs_register_attr(ancs,
		BT_ANCS_NOTIF_ATTR_ID_MESSAGE,
		attr_message, ATTR_DATA_SIZE);
	if (err) 
		goto _out;
	err = bt_ancs_register_attr(ancs,
		BT_ANCS_NOTIF_ATTR_ID_SUBTITLE,
		attr_subtitle, ATTR_DATA_SIZE);
	if (err) 
		goto _out;
	err = bt_ancs_register_attr(ancs,
		BT_ANCS_NOTIF_ATTR_ID_MESSAGE_SIZE,
		attr_message_size, ATTR_DATA_SIZE);
	if (err) 
		goto _out;
	err = bt_ancs_register_attr(ancs,
		BT_ANCS_NOTIF_ATTR_ID_DATE,
		attr_date, ATTR_DATA_SIZE);
	if (err) 
		goto _out;
	err = bt_ancs_register_attr(ancs,
		BT_ANCS_NOTIF_ATTR_ID_POSITIVE_ACTION_LABEL,
		attr_posaction, ATTR_DATA_SIZE);
	if (err) 
		goto _out;
	err = bt_ancs_register_attr(ancs,
		BT_ANCS_NOTIF_ATTR_ID_NEGATIVE_ACTION_LABEL,
		attr_negaction, ATTR_DATA_SIZE);
	if (err) 
		goto _out;
	err = bt_gattp_discovery_register(&disc_nodes);
_out:
	return err;
}

BT_CONN_CB_DEFINE(conn_callbacks) = {
	.connected = connected,
	.disconnected = disconnected,
	.security_changed = security_changed,
};

static struct bt_conn_auth_cb conn_auth_callbacks = {
	.cancel = auth_cancel,
	.pairing_complete = pairing_complete,
	.pairing_failed = pairing_failed
};


int apple_ancs_init(ancs_notification_handler_t notif_cb,
	ancs_data_handler_t data_cb) {
	int err = bt_ancs_service_init(&ancs_c);
	if (err) {
		LOG_ERR("ANCS client init failed (err %d)\n", err);
		return err;
	}
	ancs_notification_cb = notif_cb;
	ancs_data_cb = data_cb;
	return 0;
}



void bt_apple_ancs_ready(int err) {
	if (err != 0)
		LOG_ERR("Bluetooth initialize failed(%d)\n", err);
	if (IS_ENABLED(CONFIG_SETTINGS)) 
		settings_load();
	apple_ancs_init(NULL, NULL);
	err = bt_le_adv_start(BT_LE_ADV_CONN_NAME, ad, ARRAY_SIZE(ad), NULL, 0);
	if (err) {
		LOG_ERR("Advertising failed to start (err %d)\n", err);
		return;
	}
	err = bt_conn_auth_cb_register(&conn_auth_callbacks);
	if (err) 
		LOG_ERR("Failed to register authorization callbacks\n");
}
```

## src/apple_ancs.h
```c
#ifndef APPLE_ANCS_H_
#define APPLE_ANCS_H_

#include <bluetooth/services/ancs_client.h>

#ifdef __cplusplus
extern "C"{
#endif

typedef void (*ancs_notification_handler_t)(struct bt_ancs_client *ancs, 
    const struct bt_ancs_evt_notif *notif);
typedef void (*ancs_data_handler_t)(struct bt_ancs_client *ancs,
	const struct bt_ancs_attr_response *rsp);


int apple_ancs_init(ancs_notification_handler_t notif_cb,
	ancs_data_handler_t data_cb);

#ifdef __cplusplus
}
#endif
#endif /* APPLE_ANCS_H_ */
```

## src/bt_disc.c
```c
#include <errno.h>

#include <zephyr.h>
#include <bluetooth/conn.h>
#include <bluetooth/uuid.h>
#include <bluetooth/gatt.h>
#include <bluetooth/gatt_dm.h>
#include <bluetooth/services/ancs_client.h>
#include <bluetooth/services/gattp.h>

#include <logging/log.h>
#include "bt_disc.h"

LOG_MODULE_REGISTER(bt_disc);

#define DC_LIST_FOREACH(dc, head) \
    for ((dc) = (head); (dc) != NULL; (dc) = (dc)->next)

enum disc_state {
    DISC_SERVICE_CHANGED,
    DISC_SERVICE_BUSY
};

static struct bt_disc_node *dc_array;
static struct bt_disc_node *dc_pointer;
static atomic_t dc_flags;

void bt_discovery_reinit(void) {
    __ASSERT_NO_MSG(dc_array != NULL);
    struct bt_disc_node *dc;
    dc_pointer = dc_array;
    dc_flags = ATOMIC_INIT(0);
    DC_LIST_FOREACH(dc, dc_array)
        dc->found = false;
}

int bt_discovery_start(struct bt_conn *conn) {
    __ASSERT_NO_MSG(dc_array != NULL);
    if (atomic_test_and_set_bit(&dc_flags, DISC_SERVICE_BUSY))
        return 0;
    if (atomic_test_and_clear_bit(&dc_flags, DISC_SERVICE_CHANGED)) 
        dc_pointer = dc_array;
    struct bt_disc_node *dc;
    DC_LIST_FOREACH(dc, dc_pointer) {
        if (!dc->found) {
            int ret = dc->discover(conn);
            if (ret) {
                LOG_ERR("Failed to start %s discovery (err %d)\n", 
                    dc->name, ret);
            }
            dc_pointer = dc;
            return ret;
        }
    }
    return 0;
}

int bt_discovery_finish(struct bt_conn *conn, bool found) {
    if (atomic_test_and_clear_bit(&dc_flags, DISC_SERVICE_BUSY)) {
        __ASSERT_NO_MSG(dc_pointer != NULL);
        dc_pointer->found = found;
        dc_pointer = dc_pointer->next;
        return bt_discovery_start(conn);
    }
    return -EINVAL;
}

static void bt_gattp_service_changed(struct bt_gattp *gattp,
	const struct bt_gattp_handle_range *handle_range, int err) {
	if (!err) {
        atomic_set_bit(&dc_flags, DISC_SERVICE_CHANGED);
        bt_discovery_start(gattp->conn);
	}
}

static void bt_gattp_discovery_completed(struct bt_gatt_dm *dm, void *ctx) {
	struct bt_gattp *gattp = (struct bt_gattp *)ctx;
	struct bt_conn *conn = bt_gatt_dm_conn_get(dm);
	LOG_DBG("The discovery procedure for GATT Service succeeded\n");
	bt_gatt_dm_data_print(dm);
	int err = bt_gattp_handles_assign(dm, gattp);
	if (err) {
		LOG_ERR("Could not init GATT Service client object, error: %d\n", err);
	} else {
		err = bt_gattp_subscribe_service_changed(gattp, bt_gattp_service_changed);
        if (err)
            LOG_ERR("Cannot subscribe to Service Changed indication (err %d)\n", err);
	}
	err = bt_gatt_dm_data_release(dm);
	if (err) {
		LOG_ERR("Could not release the discovery data, error "
		       "code: %d\n", err);
	}
	bt_discovery_start(conn);
}

void bt_gattp_discovery_not_found(struct bt_conn *conn, void *ctx) {
	LOG_WRN("GATT Service could not be found during the discovery\n");
    bt_discovery_finish(conn, false);
}

void bt_gattp_discovery_error_found(struct bt_conn *conn, 
	int err, void *ctx) {
	LOG_WRN("The discovery procedure for GATT Service failed, err %d\n",
        err);
    bt_discovery_finish(conn, false);
}

int bt_gattp_discovery_start(struct bt_conn *conn) {
    static struct bt_gattp gattp;
    static const struct bt_gatt_dm_cb gattp_disc = {
        .completed = bt_gattp_discovery_completed,
        .service_not_found = bt_gattp_discovery_not_found,
        .error_found = bt_gattp_discovery_error_found,
    };
    bt_discovery_reinit();
    bt_gattp_init(&gattp);
    int err = bt_gatt_dm_start(conn, BT_UUID_GATT, &gattp_disc, &gattp);
	if (err) 
		LOG_ERR("Failed to start discovery for GATT Service (err %d)\n", err);
    return err;
}

int bt_gattp_discovery_register(struct bt_disc_node *node) {
    if (node == NULL)
        return -EINVAL;
    struct bt_disc_node **ptr = &dc_array;
    while (*ptr != NULL)
        ptr = &(*ptr)->next;
    node->next = NULL;
    *ptr = node;
    return 0;
}
```

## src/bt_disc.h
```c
#ifndef BT_DISC_H_
#define BT_DISC_H_

#include <stdbool.h>

#ifdef __cplusplus
extern "C"{
#endif

struct bt_conn;
struct bt_disc_node {
    struct bt_disc_node *next;
    int (*discover)(struct bt_conn *conn);
    char *name;
    bool found;
};

void bt_discovery_reinit(void);
int  bt_discovery_start(struct bt_conn *conn);
int  bt_discovery_finish(struct bt_conn *conn, bool found);

void bt_gattp_discovery_not_found(struct bt_conn *conn, void *ctx) ;
void bt_gattp_discovery_error_found(struct bt_conn *conn, 
	int err, void *ctx);
    
int bt_gattp_discovery_start(struct bt_conn *conn);
int bt_gattp_discovery_register(struct bt_disc_node *node);
#ifdef __cplusplus
}
#endif
#endif /* BT_DISC_H_ */
```

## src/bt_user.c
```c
#include <zephyr.h>

#include <bluetooth/bluetooth.h>
#include <bluetooth/conn.h>
#include <bluetooth/gatt.h>
#include <bluetooth/hci.h>
#include <bluetooth/uuid.h>

#include <bluetooth/gatt_dm.h>
#include <bluetooth/services/ancs_client.h>
#include <bluetooth/services/gattp.h>

#include <logging/log.h>
#include <settings/settings.h>

#include "bt_disc.h"
#include "apple_ancs.h"
#include "apple_ams.h"

LOG_MODULE_REGISTER(bt_user);

#define DEVICE_NAME CONFIG_BT_DEVICE_NAME
#define DEVICE_NAME_LEN (sizeof(DEVICE_NAME) - 1)

static struct bt_conn *user_conn;

static const struct bt_data ad[] = {
    BT_DATA_BYTES(BT_DATA_FLAGS, (BT_LE_AD_GENERAL | BT_LE_AD_NO_BREDR)),
    BT_DATA_BYTES(BT_DATA_UUID16_ALL, BT_UUID_16_ENCODE(BT_UUID_HRS_VAL),
                  BT_UUID_16_ENCODE(BT_UUID_BAS_VAL),
                  BT_UUID_16_ENCODE(BT_UUID_DIS_VAL)),
    BT_DATA(BT_DATA_NAME_COMPLETE, DEVICE_NAME, DEVICE_NAME_LEN)
};


static void exchange_done(struct bt_conn *conn, uint8_t err,
	struct bt_gatt_exchange_params *params) {
    int ec;
    if (err != 0) {
        LOG_ERR("Gatt exchange parameters failed(%d)\n", (int)err);
        return;
    }
    LOG_INFO("MTU has been updated to %d\n", bt_gatt_get_mtu(conn));
#if 0
    struct bt_conn_info info;
    ec = bt_conn_get_info(conn, &info);
    if (ec) {
        LOG_ERR("Get connect information failed(%d"\n, ec);
        return;
    }
#endif
}

static int bt_user_exchange_mtu(struct bt_conn *conn) {
    static struct bt_gatt_exchange_params param = {
        .func = exchange_done
    };
	return bt_gatt_exchange_mtu(conn, &param);
}

static void bt_user_connected(struct bt_conn *conn, uint8_t err) {
	char addr[BT_ADDR_LE_STR_LEN];
    int ret;
	if (err) {
		LOG_ERR("Connection failed (err 0x%02x)\n", err);
		return;
	}
    user_conn = bt_conn_ref(conn);
	bt_addr_le_to_str(bt_conn_get_dst(conn), addr, sizeof(addr));
	ret = bt_conn_set_security(conn, BT_SECURITY_L2);
	if (ret) {
		LOG_ERR("Failed to set security (err %d)\n", ret);
        return;
	}
    ret = bt_user_exchange_mtu(conn);
    if (ret) {
        LOG_ERR("GATT exchange mtu failed(%d)\n", ret);
        return;
    }
}

static void bt_user_disconnected(struct bt_conn *conn, uint8_t reason) {
	char addr[BT_ADDR_LE_STR_LEN];
    if (user_conn == conn) {
        bt_conn_unref(user_conn);
        user_conn = NULL;
    }
	bt_addr_le_to_str(bt_conn_get_dst(conn), addr, sizeof(addr));
	LOG_INF("Disconnected from %s (reason 0x%02x)\n", addr, reason);
}

static void bt_user_security_changed(struct bt_conn *conn, bt_security_t level,
	enum bt_security_err err) {
	char addr[BT_ADDR_LE_STR_LEN];
	bt_addr_le_to_str(bt_conn_get_dst(conn), addr, sizeof(addr));
	if (!err) {
		LOG_INF("Security changed: %s level %u\n", addr, level);
		if (bt_conn_get_security(conn) >= BT_SECURITY_L2) {
			bt_gattp_discovery_start(conn);
		}
	} else {
		LOG_ERR("Security failed: %s level %u err %d\n", 
			addr, level, err);  
	}
}

static void bt_user_auth_cancel(struct bt_conn *conn) {
	char addr[BT_ADDR_LE_STR_LEN];
	bt_addr_le_to_str(bt_conn_get_dst(conn), addr, sizeof(addr));
	LOG_INF("Pairing cancelled: %s\n", addr);
	bt_conn_disconnect(conn, BT_HCI_ERR_REMOTE_USER_TERM_CONN);
}

static void bt_user_pairing_complete(struct bt_conn *conn, bool bonded) {
	char addr[BT_ADDR_LE_STR_LEN];
	bt_addr_le_to_str(bt_conn_get_dst(conn), addr, sizeof(addr));
	LOG_INF("Pairing completed: %s, bonded: %d\n", addr, bonded);
}

static void bt_user_pairing_failed(struct bt_conn *conn, 
	enum bt_security_err reason) {
	char addr[BT_ADDR_LE_STR_LEN];
	bt_addr_le_to_str(bt_conn_get_dst(conn), addr, sizeof(addr));
	LOG_ERR("Pairing failed conn: %s, reason %d\n", addr, reason);
	bt_conn_disconnect(conn, BT_HCI_ERR_REMOTE_USER_TERM_CONN);
}

BT_CONN_CB_DEFINE(conn_callbacks) = {
	.connected = bt_user_connected,
	.disconnected = bt_user_disconnected,
	.security_changed = bt_user_security_changed
};

static struct bt_conn_auth_cb conn_auth_callbacks = {
	.cancel = bt_user_auth_cancel,
	.pairing_complete = bt_user_pairing_complete,
	.pairing_failed = bt_user_pairing_failed
};

void bt_post_action(int err) {
	if (err != 0) {
		LOG_ERR("Bluetooth initialize failed(%d)\n", err);
        return;
    }
	if (IS_ENABLED(CONFIG_SETTINGS)) 
		settings_load();
	if (IS_ENABLED(CONFIG_BT_ANCS_CLIENT)) {
	    err = apple_ancs_init(NULL, NULL);
		if (err)
			LOG_ERR("ANCS initialize failed(%d)\n", err);
	}
    if (IS_ENABLED(CONFIG_BT_AMS_CLIENT)) {
		err = apple_ams_init();
		if (err)
			LOG_ERR("AMS initialize failed(%d)\n", err);
	}
	err = bt_le_adv_start(BT_LE_ADV_CONN, ad, ARRAY_SIZE(ad), NULL, 0);
	if (err) {
		LOG_ERR("Advertising failed to start (err %d)\n", err);
		return;
	}
	err = bt_conn_auth_cb_register(&conn_auth_callbacks);
	if (err) 
		LOG_ERR("Failed to register authorization callbacks\n");
}
```

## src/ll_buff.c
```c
/*
 * CopyRight 2022 wtcat
 */

#include <errno.h>
#include <stdio.h>
#include <string.h>

#ifdef __ZEPHYR__
#include <sys/cbprintf.h>
#endif

#include "ll_buff.h"


#ifndef MIN
#define MIN(a, b) (((a) < (b)) ? (a) : (b))
#endif

#ifndef __noinit
#define __noinit 
#endif


#define LOG_RAM (&_ll_log_buffer)

static struct ll_buffer_context _ll_log_buffer __attribute__((section(".ram_reserved.ll_buff")));
struct ll_buffer_context *_ll_log_context = LOG_RAM;

struct ll_printer _ll_log_printer = {
	.context = LOG_RAM,
	.print = ll_buffer_context_print
};
	static struct k_spinlock ll_lock;
k_spinlock_key_t k_spin_lock(struct k_spinlock *l);

static void ll_out(int c, void *ctx) {
	struct ll_buffer_context *bc = ctx;
	bc->buffer[bc->wrp++] = (char)c;
	if (bc->wrp >= LL_BUFF_LEN) {
		bc->full = true;
		bc->wrp = 0;
	}
	if (bc->full)
		bc->rdp = bc->wrp + 1;
}

int ll_buffer_context_print(void *ctx, const char *fmt, va_list ap) {
	struct ll_buffer_context *bc = ctx;
	k_spinlock_key_t key = k_spin_lock(&bc->lock);
	if (!ll_buffer_context_ready(bc))
		ll_buffer_context_reset(bc);
	if (bc->rdlock) {
		k_spin_unlock(&bc->lock, key);
		return -EBUSY;
	}
	int len = cbvprintf(ll_out, ctx, fmt, ap);
	k_spin_unlock(&bc->lock, key);
	return len;
}

size_t ll_buffer_context_read(struct ll_buffer_context *bc, char *dst, 
	size_t maxlen, size_t *offset) {
	k_spinlock_key_t key = k_spin_lock(&bc->lock);
	if (!ll_buffer_context_ready(bc)) {
		k_spin_unlock(&bc->lock, key);
		return 0;
	}
	size_t ofs = *offset;
	char *buffer = dst;
	while (maxlen > 0) {
		size_t len;
		if (ofs > bc->wrp)
			len = MIN(maxlen, LL_BUFF_LEN - ofs);
		else
			len = MIN(maxlen, bc->wrp - ofs);
		if (len == 0)
			break;
		memcpy(buffer, &bc->buffer[ofs], len);
		buffer += len;
		maxlen -= len;
		LL_BUFF_POINTER_ADD(ofs, len); 
	}
	k_spin_unlock(&bc->lock, key);
	*offset = ofs;
	return (size_t)(buffer - dst);
}

void ll_buffer_context_dump(struct ll_buffer_context *buff, 
	int (*putc)(int c)) {
	char buffer[64];
	if (putc == NULL)
		return;
	ll_buffer_copy(buffer, sizeof(buffer), 
		for (int i = 0; i < buffer_len; i++) {putc(buffer[i]);});
}
```
